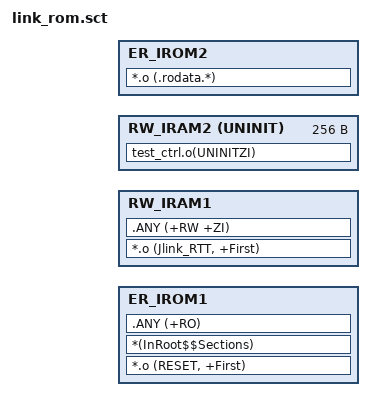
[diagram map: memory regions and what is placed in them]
#! armclang -E --target=arm-arm-none-eabi -mcpu=cortex-m33 -xc
#include "../../../../cmsis/sf32lb58x/mem_map.h"


; *************************************************************
; *** Scatter-Loading Description File generated by uVision ***
; *************************************************************

LR_IROM1 ROM_BASE ROM_SIZE  {    ; load region size_region
  ER_IROM1 ROM_BASE ROM_SIZE  {  ; load address = execution address
   *.o (RESET, +First)
   *(InRoot$$Sections)
   .ANY (+RO)
  }
  RW_IRAM1 HCPU_RAM_DATA_START_ADDR HCPU_RAM_DATA_SIZE-0x100  {  ; RW data  
   *.o (Jlink_RTT, +First)
   .ANY (+RW +ZI)
  }
  RW_IRAM2 HCPU_RAM_DATA_START_ADDR+HCPU_RAM_DATA_SIZE-0x100 UNINIT 0x100  {  ; RW data  
  test_ctrl.o(UNINITZI)
  }
}


LR_IROM2 HCPU_RO_DATA_START_ADDR HCPU_RO_DATA_SIZE  {    ; load region size_region
  ER_IROM2 HCPU_RO_DATA_START_ADDR HCPU_RO_DATA_SIZE  {  ; load address = execution address
   *.o (.rodata.*)
  }
}

;LR_IROM3 RAM6_BASE RAM6_SIZE  {  ; load region size_region
;  RW_IRAM6 RAM6_BASE RAM6_SIZE  {  ; RW data
;   *.o (.bss.KWS_BUFFER1)
;   *.o (KWS_BIAS)
;  }
;  RW_IRAM7 RAM7_BASE RAM7_SIZE  {  ; RW data
;   *.o (KWS_WT)
;  }
;  RW_IRAM8 RAM8_BASE RAM8_SIZE  {  ; RW data
;   *.o (.bss.KWS_BUFFER2)
;   *.o (KWS_BIAS2)
;  }
;}


